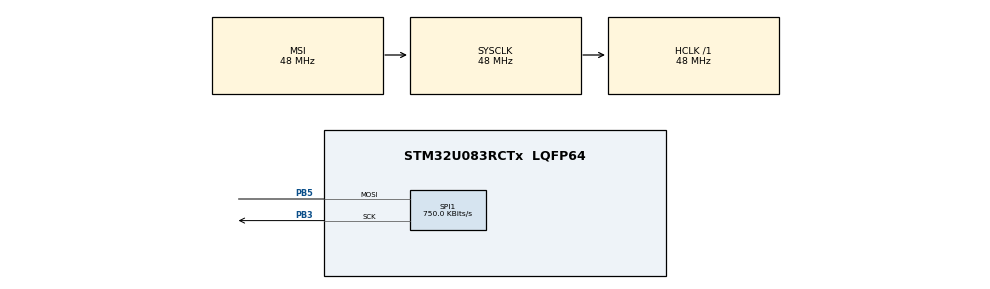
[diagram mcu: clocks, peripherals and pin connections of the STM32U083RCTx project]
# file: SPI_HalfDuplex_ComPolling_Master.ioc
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Mcu.Family=STM32U0
Mcu.Name=STM32U083RCTx
Mcu.Package=LQFP64
NVIC.PriorityGroup=NVIC_PRIORITYGROUP_2
PB3.GPIO_PuPd=GPIO_PULLDOWN
PB3.GPIO_Speed=GPIO_SPEED_FREQ_VERY_HIGH
PB3.Mode=Simplex_Bidirectional_Master
PB3.Signal=SPI1_SCK
PB5.GPIO_PuPd=GPIO_PULLDOWN
PB5.GPIO_Speed=GPIO_SPEED_FREQ_VERY_HIGH
PB5.Mode=Simplex_Bidirectional_Master
PB5.Signal=SPI1_MOSI
ProjectManager.HeapSize=0x200
ProjectManager.StackSize=0x400
ProjectManager.TargetToolchain=EWARM V9.20
RCC.ADCFreq_Value=48000000
RCC.AHBFreq_Value=48000000
RCC.CortexFreq_Value=48000000
RCC.HCLKFreq_Value=48000000
RCC.HSE_VALUE=4000000
RCC.HSI48_VALUE=48000000
RCC.HSI_VALUE=16000000
RCC.LSE_VALUE=32768
RCC.MSIClockRangeVal=RCC_MSIRANGE_11
RCC.MSI_VALUE=48000000
RCC.PLLM=RCC_PLLM_DIV8
RCC.PLLN=8
RCC.PLLSourceVirtual=RCC_PLLSOURCE_MSI
RCC.SYSCLKFreq_VALUE=48000000
RCC.SYSCLKSource=RCC_SYSCLKSOURCE_MSI
RCC.USBFreq_Value=48000000
RCC.VCOOutputFreq_Value=48000000
SPI1.BAUDRATEPRESCALER=SPI_BAUDRATEPRESCALER_8
SPI1.BaudRatePrescaler=SPI_BAUDRATEPRESCALER_64
SPI1.CLKPhase=SPI_PHASE_1EDGE
SPI1.CLKPolarity=SPI_POLARITY_LOW
SPI1.CRCCalculation=SPI_CRCCALCULATION_DISABLE
SPI1.CalculateBaudRate=750.0 KBits/s
SPI1.DataSize=SPI_DATASIZE_8BIT
SPI1.Direction=SPI_DIRECTION_1LINE
SPI1.FirstBit=SPI_FIRSTBIT_MSB
SPI1.GPIO_SPEED=GPIO_SPEED_FREQ_HIGH
SPI1.Mode=SPI_MODE_MASTER
SPI1.NSS=SPI_NSS_SOFT
SPI1.NSSPMode=SPI_NSS_PULSE_DISABLE
SPI1.TIMode=SPI_TIMODE_DISABLE
SPI1.VirtualType=VM_MASTER
VP_PWR_VS_SECSignals.Mode=Security/Privilege
board=custom

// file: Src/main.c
/* USER CODE BEGIN Header */
/**
  ******************************************************************************
  * @file           : main.c
  * @brief          : Main program body
  ******************************************************************************
  * @attention
  *
  * Copyright (c) 2023 STMicroelectronics.
  * All rights reserved.
  *
  * This software is licensed under terms that can be found in the LICENSE file
  * in the root directory of this software component.
  * If no LICENSE file comes with this software, it is provided AS-IS.
  *
  ******************************************************************************
  */
/* USER CODE END Header */
#include "main.h"

/* USER CODE BEGIN Includes */
#include "stm32u0xx_nucleo.h"
/* USER CODE END Includes */

SPI_HandleTypeDef hspi1;

/* USER CODE BEGIN PV */
/* Private macro -------------------------------------------------------------*/
#define SYNCHRO_WAIT(NB)       for(int i=0; i<NB; i++){__asm("dsb\n");}
#define DELAY_SLAVE_RECONFIG   600 /* Used with SYNCHRO_WAIT */

#define READ_REGISTER          0x80
#define COMMAND_COUNTER        0x0F
#define COMMAND_COUNTER_ADD    0x01
#define COMMAND_COUNTER_SUB    0x02

/* Private variables ---------------------------------------------------------*/
/* Buffer used for transmission */
uint8_t aTxBuffer[2];

/* Buffer used for reception */
uint8_t aRxBuffer[2];

uint8_t counter_local = 20, counter_remote;

/* USER CODE END PV */

void SystemClock_Config(void);
static void MX_GPIO_Init(void);
static void MX_SPI1_Init(void);
/* USER CODE BEGIN PFP */
/* Private function prototypes -----------------------------------------------*/
static void SPI_Write(uint8_t val);
static void SPI_Read(uint8_t *val);
static void Command_write(uint8_t command, uint8_t val);
static void Command_read(uint8_t command, uint8_t *val);

/* USER CODE END PFP */

int main(void)
{

  /* MCU Configuration--------------------------------------------------------*/

  /* Reset of all peripherals, Initializes the Flash interface and the Systick. */
  HAL_Init();

  /* Configure the system clock */
  SystemClock_Config();

  /* Initialize all configured peripherals */
  MX_GPIO_Init();
  MX_SPI1_Init();
  /* USER CODE BEGIN 2 */

  /* Configure LED4 */
  BSP_LED_Init(LED4);

  /* Configure User push-button */
  BSP_PB_Init(BUTTON_USER, BUTTON_MODE_GPIO);
  /* Wait for User push-button press before starting the Communication */
  while (BSP_PB_GetState(BUTTON_USER) != GPIO_PIN_RESET)
  {
    BSP_LED_Toggle(LED4);
    HAL_Delay(100);
  }
  BSP_LED_Off(LED4);

  /* Enable the SPI to allow communication */
  SPI_1LINE_TX(&hspi1);
  __HAL_SPI_ENABLE(&hspi1);

  /* Initialize the remote counter */
  Command_write(COMMAND_COUNTER, counter_local);

  /*## Read the remote counter value */
  Command_read(COMMAND_COUNTER, &counter_remote);

  if(counter_local != counter_remote)
  {
    Error_Handler();
  }

  /* USER CODE END 2 */

  /* Infinite loop */
  /* USER CODE BEGIN WHILE */
  while (1)
  {
    /*## Execute the command counter add */
    counter_local += 7;
    Command_write(COMMAND_COUNTER_ADD, 7);
    Command_read(COMMAND_COUNTER, &counter_remote);

    if(counter_local != counter_remote)
    {
      Error_Handler();
    }

    /*## Execute the command counter sub */
    counter_local -= 2;
    Command_write(COMMAND_COUNTER_SUB, 2);
    Command_read(COMMAND_COUNTER, &counter_remote);

    if(counter_local != counter_remote)
    {
      Error_Handler();
    }

    /* Infinite loop */
    HAL_Delay(50);
    BSP_LED_Toggle(LED4);
    /* USER CODE END WHILE */

  }
}

void SystemClock_Config(void)
{
  RCC_OscInitTypeDef RCC_OscInitStruct = {0};
  RCC_ClkInitTypeDef RCC_ClkInitStruct = {0};

  /** Configure the main internal regulator output voltage
  */
  HAL_PWREx_ControlVoltageScaling(PWR_REGULATOR_VOLTAGE_SCALE1);

  /** Initializes the RCC Oscillators according to the specified parameters
  * in the RCC_OscInitTypeDef structure.
  */
  RCC_OscInitStruct.OscillatorType = RCC_OSCILLATORTYPE_MSI;
  RCC_OscInitStruct.MSIState = RCC_MSI_ON;
  RCC_OscInitStruct.MSICalibrationValue = RCC_MSICALIBRATION_DEFAULT;
  RCC_OscInitStruct.MSIClockRange = RCC_MSIRANGE_11;
  RCC_OscInitStruct.PLL.PLLState = RCC_PLL_NONE;
  if (HAL_RCC_OscConfig(&RCC_OscInitStruct) != HAL_OK)
  {
    Error_Handler();
  }

  /** Initializes the CPU, AHB and APB buses clocks
  */
  RCC_ClkInitStruct.ClockType = RCC_CLOCKTYPE_HCLK|RCC_CLOCKTYPE_SYSCLK
                              |RCC_CLOCKTYPE_PCLK1;
  RCC_ClkInitStruct.SYSCLKSource = RCC_SYSCLKSOURCE_MSI;
  RCC_ClkInitStruct.AHBCLKDivider = RCC_SYSCLK_DIV1;
  RCC_ClkInitStruct.APB1CLKDivider = RCC_HCLK_DIV1;

  if (HAL_RCC_ClockConfig(&RCC_ClkInitStruct, FLASH_LATENCY_1) != HAL_OK)
  {
    Error_Handler();
  }
}

static void MX_SPI1_Init(void)
{

  /* SPI1 parameter configuration*/
  hspi1.Instance = SPI1;
  hspi1.Init.Mode = SPI_MODE_MASTER;
  hspi1.Init.Direction = SPI_DIRECTION_1LINE;
  hspi1.Init.DataSize = SPI_DATASIZE_8BIT;
  hspi1.Init.CLKPolarity = SPI_POLARITY_LOW;
  hspi1.Init.CLKPhase = SPI_PHASE_1EDGE;
  hspi1.Init.NSS = SPI_NSS_SOFT;
  hspi1.Init.BaudRatePrescaler = SPI_BAUDRATEPRESCALER_64;
  hspi1.Init.FirstBit = SPI_FIRSTBIT_MSB;
  hspi1.Init.TIMode = SPI_TIMODE_DISABLE;
  hspi1.Init.CRCCalculation = SPI_CRCCALCULATION_DISABLE;
  hspi1.Init.CRCPolynomial = 7;
  hspi1.Init.CRCLength = SPI_CRC_LENGTH_DATASIZE;
  hspi1.Init.NSSPMode = SPI_NSS_PULSE_DISABLE;
  if (HAL_SPI_Init(&hspi1) != HAL_OK)
  {
    Error_Handler();
  }

}

static void MX_GPIO_Init(void)
{

  /* GPIO Ports Clock Enable */
  __HAL_RCC_GPIOB_CLK_ENABLE();

}

/* USER CODE BEGIN 4 */

/**
  * @brief  This function send a command through SPI bus.
  * @param  command : command id.
  * @param  val : value.
  * @retval None
  */
void SPI_Write(uint8_t val)
{
  /* check TXE flag */
  while((hspi1.Instance->SR & SPI_FLAG_TXE) != SPI_FLAG_TXE);

  /* Write the data */
  *((__IO uint8_t*)&hspi1.Instance->DR) = val;

  /* Wait BSY flag */
  while((hspi1.Instance->SR & SPI_FLAG_FTLVL) != SPI_FTLVL_EMPTY);
  while((hspi1.Instance->SR & SPI_FLAG_BSY) == SPI_FLAG_BSY);
}

/**
  * @brief  This function send a command through SPI bus.
  * @param  command : command id.
  * @param  val : value.
  * @retval None
  */
void SPI_Read(uint8_t *val)
{
   /* In master RX mode the clock is automatically generated on the SPI enable.
      So to guarantee the clock generation for only one data, the clock must be
      disabled after the first bit and before the latest bit */
  __HAL_SPI_ENABLE(&hspi1);
  __asm("dsb\n");
  __asm("dsb\n");
  __asm("dsb\n");
  __asm("dsb\n");
  __HAL_SPI_DISABLE(&hspi1);

  while((hspi1.Instance->SR & SPI_FLAG_RXNE) != SPI_FLAG_RXNE);
  /* read the received data */
  *val = *(__IO uint8_t *)&hspi1.Instance->DR;
  while((hspi1.Instance->SR & SPI_FLAG_BSY) == SPI_FLAG_BSY);
}

/**
  * @brief  This function send a command through SPI bus.
  * @param  command : command id.
  * @param  val : value.
  * @retval None
  */
void Command_write(uint8_t command, uint8_t val)
{
  SPI_Write(command);
  SPI_Write(val);
}

/**
  * @brief  This function send a command through SPI bus.
  * @param  command : command id.
  * @param  val : value.
  * @retval None
  */
void Command_read(uint8_t command, uint8_t *val)
{
  SPI_Write(command | READ_REGISTER);
  __HAL_SPI_DISABLE(&hspi1);
  SYNCHRO_WAIT(DELAY_SLAVE_RECONFIG);
  SPI_1LINE_RX(&hspi1);
  SPI_Read(val);
  SPI_1LINE_TX(&hspi1);
  __HAL_SPI_ENABLE(&hspi1);
}

/* USER CODE END 4 */

void Error_Handler(void)
{
  __disable_irq();
  while (1)
  {
  }
}
